# APM32F411 register map
File version: 1.0
CPU: CM4 r1p0, little endian, no MPU, no FPU, 3 interrupt priority bits
Registers are 32-bit, read-write, reset 0x0 unless marked. A register's access mark holds for its fields unless they carry their own. Offsets are from the block's base; [hi:lo] are bit positions; {n}, {i} and the like mark numbered series.

## DBGMCU — Debug support
Base 0xE0042000
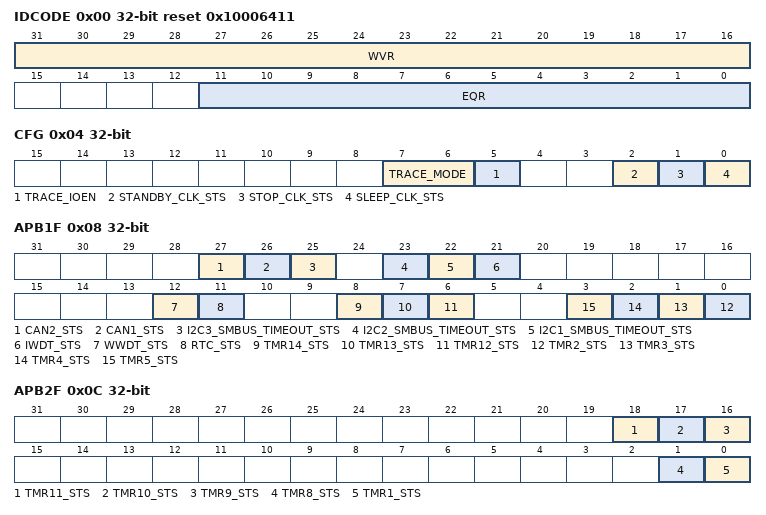
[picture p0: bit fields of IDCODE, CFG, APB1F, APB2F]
0x00 IDCODE ro reset 0x10006411
  [31:16] WVR — Wafer Version Recognition
  [11:0] EQR — Equipment Recognition
0x04 CFG — Control Register
  [7:6] TRACE_MODE — Trace Debug Pin Mode Configure
  [5] TRACE_IOEN — Trace Debug Pin Enable
  [2] STANDBY_CLK_STS — Configure clock status when MCU is debugged in standby mode
  [1] STOP_CLK_STS — Configure clock status when MCU is debugged in stop mode
  [0] SLEEP_CLK_STS — Configure clock status when MCU is debugged in sleep mode
0x08 APB1F — Debug MCU APB1 Freeze registe
  [27] CAN2_STS — CAN2 counter stopped when core is halted
  [26] CAN1_STS — CAN1 counter stopped when core is halted
  [25] I2C3_SMBUS_TIMEOUT_STS
  [23] I2C2_SMBUS_TIMEOUT_STS
  [22] I2C1_SMBUS_TIMEOUT_STS
  [21] IWDT_STS — IWDT counter stopped when core is halted
  [12] WWDT_STS — WWDT counter stopped when core is halted
  [11] RTC_STS — RTC counter stopped when core is halted
  [8] TMR14_STS — TMR14 counter stopped when core is halted
  [7] TMR13_STS — TMR13 counter stopped when core is halted
  [6] TMR12_STS — TMR12 counter stopped when core is halted
  [n-2] TMR{n}_STS (n=2..5) — TMR{n} counter stopped when core is halted
0x0C APB2F — Debug MCU APB2 Freeze registe
  [18] TMR11_STS — TMR11 counter stopped when core is halted
  [17] TMR10_STS — TMR10 counter stopped when core is halted
  [16] TMR9_STS — TMR9 counter stopped when core is halted
  [1] TMR8_STS — TMR8 counter stopped when core is halted
  [0] TMR1_STS — TMR1 counter stopped when core is halted

## SYSCFG — System configuration controller
Base 0x40013800
0x00 MMSEL — memory remap register
  [1:0] MMSEL — Memory Mapping Select
0x04 PMCFG — peripheral mode configuration register
  [16] ADCx02EN — ADCx Option 2 Enable
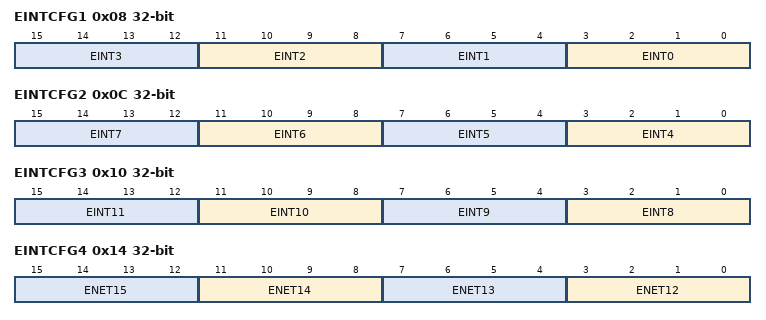
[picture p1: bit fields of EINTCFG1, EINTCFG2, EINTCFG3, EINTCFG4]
0x08 EINTCFG1 — external interrupt configuration register 1
  [4n+3:4n] EINT{n} (n=0..3) — EINTx Configure
0x0C EINTCFG2 — external interrupt configuration register 2
  [4n-13:4n-16] EINT{n} (n=4..7) — EINTx Configure
0x10 EINTCFG3 — external interrupt configuration register 3
  [4n-29:4n-32] EINT{n} (n=8..11) — EINTx Configure
0x14 EINTCFG4 — external interrupt configuration register 4
  [4n-45:4n-48] ENET{n} (n=12..15) — EINTx Configure
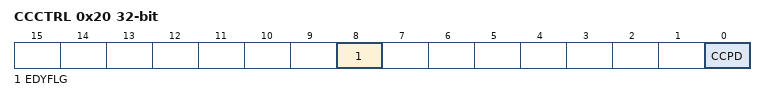
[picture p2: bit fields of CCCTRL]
0x20 CCCTRL access per field — Compensation cell control register
  [8] EDYFLG ro — Compensation Cell Ready Flag
  [0] CCPD rw — Compensation Cell Power-down

## COMP1 — Comparator
Base 0x40013818
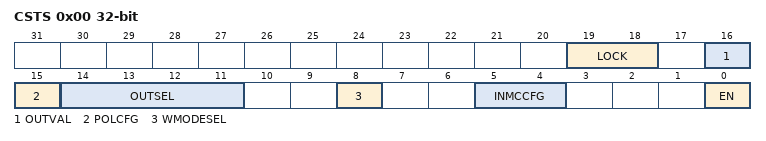
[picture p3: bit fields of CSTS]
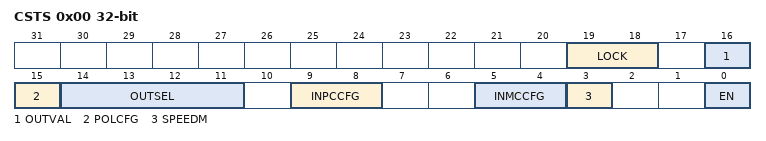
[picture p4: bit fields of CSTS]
0x00 CSTS — control and status register
  [19:18] LOCK — COMP CSTS Register Lock
  [16] OUTVAL — Comparator 1 output status
  [15] POLCFG — Comparator 1 Polarity Configure
  [14:11] OUTSEL — Comparator 1 output Selest
  [8] WMODESEL — Comparator 1 Window Mode Select
  [5:4] INMCCFG — Comparator 1 Input Minus Connection Configure
  [0] EN — Comparator 1 enable

## COMP2 — Comparator
Base 0x4001381C
0x00 CSTS — control and status register
  [19:18] LOCK — COMP CSTS Register Lock
  [16] OUTVAL — Comparator output status
  [15] POLCFG — Comparator Polarity Configure
  [14:11] OUTSEL — Comparator output Selest
  [9:8] INPCCFG — Comparator Input Plus Connection Configure
  [5:4] INMCCFG — Comparator Input Minus Connection Configure
  [3] SPEEDM — Comparator Speed Mode Select
  [0] EN — Comparator enable

## USART6 — Universal synchronous asynchronous receiver transmitter
Base 0x40011400
Same registers: USART2 0x40004400, USART3 0x40004800, USART1 0x40011000
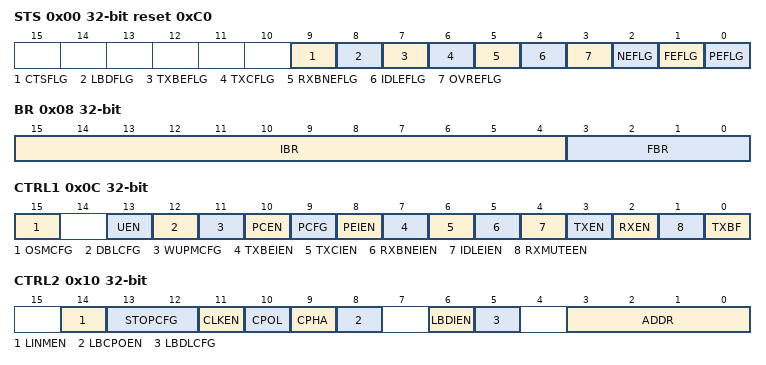
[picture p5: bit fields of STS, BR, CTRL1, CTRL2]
0x00 STS access per field reset 0xC0 — Status register
  [9] CTSFLG rw — CTS flag
  [8] LBDFLG rw — LIN break detection flag
  [7] TXBEFLG ro — Transmit data register empty
  [6] TXCFLG rw — Transmission complete
  [5] RXBNEFLG rw — Read data register not empty
  [4] IDLEFLG ro — IDLE line detected
  [3] OVREFLG ro — Overrun error
  [2] NEFLG ro — Noise detected flag
  [1] FEFLG ro — Framing error
  [0] PEFLG ro — Parity error
0x04 DATA
  [8:0] DATA — Data value
0x08 BR — Baud rate register
  [15:4] IBR — mantissa of USARTDIV
  [3:0] FBR — fraction of USARTDIV
0x0C CTRL1 — Control register 1
  [15] OSMCFG — Oversampling mode
  [13] UEN — USART enable
  [12] DBLCFG — Word length
  [11] WUPMCFG — Wakeup method
  [10] PCEN — Parity control enable
  [9] PCFG — Parity selection
  [8] PEIEN — Parity Error Interrupt Enable
  [7] TXBEIEN — Transmit Buffer Empty Interrupt Enable
  [6] TXCIEN — Transmission complete interrupt enable
  [5] RXBNEIEN — RXNE interrupt enable
  [4] IDLEIEN — IDLE interrupt enable
  [3] TXEN — Transmitter enable
  [2] RXEN — Receiver enable
  [1] RXMUTEEN — Receiver wakeup
  [0] TXBF — Send break
0x10 CTRL2 — Control register 2
  [14] LINMEN — LIN mode enable
  [13:12] STOPCFG — STOP bits
  [11] CLKEN — Clock enable
  [10] CPOL — Clock polarity
  [9] CPHA — Clock phase
  [8] LBCPOEN — Last bit clock pulse
  [6] LBDIEN — LIN break detection interrupt enable
  [5] LBDLCFG — lin break detection length
  [3:0] ADDR — Address of the USART node
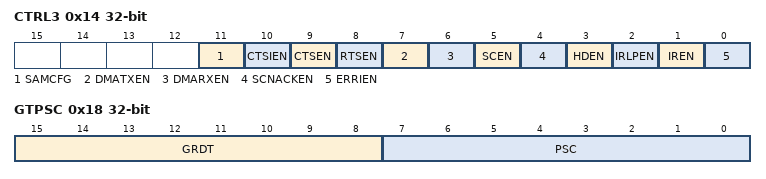
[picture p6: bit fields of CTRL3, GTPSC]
0x14 CTRL3 — Control register 3
  [11] SAMCFG — One sample bit method enable
  [10] CTSIEN — CTS interrupt enable
  [9] CTSEN — CTS enable
  [8] RTSEN — RTS enable
  [7] DMATXEN — DMA enable transmitter
  [6] DMARXEN — DMA enable receiver
  [5] SCEN — Smartcard mode enable
  [4] SCNACKEN — Smartcard NACK enable
  [3] HDEN — Half-duplex selection
  [2] IRLPEN — IrDA low-power
  [1] IREN — IrDA mode enable
  [0] ERRIEN — Error interrupt enable
0x18 GTPSC — Guard time and prescaler register
  [15:8] GRDT — Guard time value
  [7:0] PSC — Prescaler value
